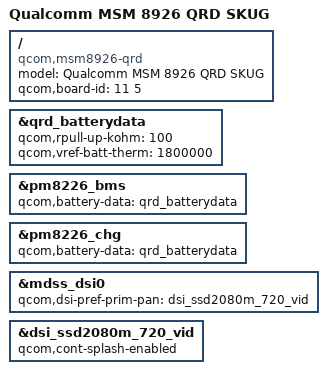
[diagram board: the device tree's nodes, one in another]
/* Copyright (c) 2013, The Linux Foundation. All rights reserved.
 *
 * This program is free software; you can redistribute it and/or modify
 * it under the terms of the GNU General Public License version 2 and
 * only version 2 as published by the Free Software Foundation.
 *
 * This program is distributed in the hope that it will be useful,
 * but WITHOUT ANY WARRANTY; without even the implied warranty of
 * MERCHANTABILITY or FITNESS FOR A PARTICULAR PURPOSE.  See the
 * GNU General Public License for more details.
 */

/dts-v1/;
/include/ "msm8926.dtsi"
/include/ "msm8226-qrd.dtsi"
/include/ "msm8926-camera-sensor-qrd.dtsi"

/ {
	model = "Qualcomm MSM 8926 QRD SKUG";
	compatible = "qcom,msm8926-qrd", "qcom,msm8926", "qcom,qrd";
	qcom,board-id = <11 5>;
};

&qrd_batterydata {
	qcom,rpull-up-kohm = <100>;
	qcom,vref-batt-therm = <1800000>;

	/include/ "batterydata-qrd-4v2-2000mah.dtsi"
};

&pm8226_bms {
	qcom,battery-data = <&qrd_batterydata>;
};

&pm8226_chg {
	qcom,battery-data = <&qrd_batterydata>;
};

&mdss_dsi0 {
	qcom,dsi-pref-prim-pan = <&dsi_ssd2080m_720_vid>;
};

&dsi_ssd2080m_720_vid {
	qcom,cont-splash-enabled;
};
